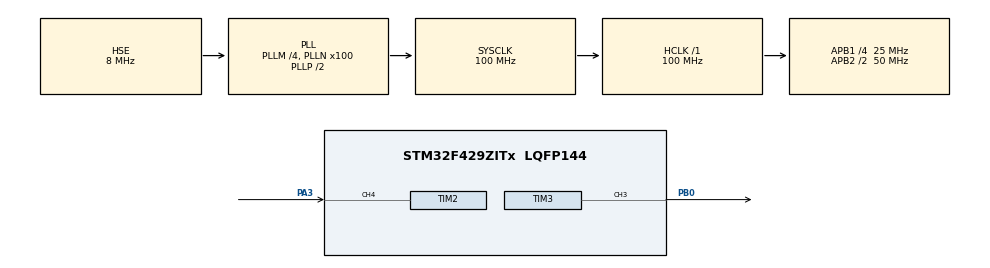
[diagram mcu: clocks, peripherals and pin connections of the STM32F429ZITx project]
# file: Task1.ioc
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Mcu.Family=STM32F4
Mcu.Name=STM32F429ZITx
Mcu.Package=LQFP144
NVIC.PriorityGroup=NVIC_PRIORITYGROUP_4
NVIC.TIM2_IRQn=true\:0\:0\:false\:false\:true\:true\:true
NVIC.TIM3_IRQn=true\:0\:0\:false\:false\:true\:true\:true
PA3.Signal=S_TIM2_CH4
PB0.Signal=S_TIM3_CH3
PH0/OSC_IN.Mode=HSE-External-Oscillator
PH0/OSC_IN.Signal=RCC_OSC_IN
PH1/OSC_OUT.Mode=HSE-External-Oscillator
PH1/OSC_OUT.Signal=RCC_OSC_OUT
ProjectManager.HeapSize=0x200
ProjectManager.StackSize=0x400
ProjectManager.TargetToolchain=EWARM V8.32
RCC.48MHZClocksFreq_Value=50000000
RCC.AHBFreq_Value=100000000
RCC.APB1CLKDivider=RCC_HCLK_DIV4
RCC.APB1Freq_Value=25000000
RCC.APB1TimFreq_Value=50000000
RCC.APB2CLKDivider=RCC_HCLK_DIV2
RCC.APB2Freq_Value=50000000
RCC.APB2TimFreq_Value=100000000
RCC.CortexFreq_Value=100000000
RCC.HCLKFreq_Value=100000000
RCC.HSE_VALUE=8000000
RCC.HSI_VALUE=16000000
RCC.LSE_VALUE=32768
RCC.PLLM=4
RCC.PLLN=100
RCC.PLLSourceVirtual=RCC_PLLSOURCE_HSE
RCC.SYSCLKFreq_VALUE=100000000
RCC.SYSCLKSource=RCC_SYSCLKSOURCE_PLLCLK
RCC.VCOOutputFreq_Value=200000000
SH.S_TIM2_CH4.0=TIM2_CH4,Input_Capture4_from_TI4
SH.S_TIM3_CH3.0=TIM3_CH3,Output Compare3 CH3
TIM2.Channel-Input_Capture4_from_TI4=TIM_CHANNEL_4
TIM2.ICPolarity_CH4=TIM_INPUTCHANNELPOLARITY_RISING
TIM2.Period=0xfffff-1
TIM2.Prescaler=99
TIM3.Channel-Output\ Compare3\ CH3=TIM_CHANNEL_3
TIM3.Period=0xffff-1
TIM3.Prescaler=99
VP_TIM2_VS_ClockSourceINT.Mode=Internal
VP_TIM3_VS_ClockSourceINT.Mode=Internal
VP_TIM4_VS_ClockSourceINT.Mode=Internal
board=custom

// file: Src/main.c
/* USER CODE BEGIN Header */
/**
  ******************************************************************************
  * @file           : main.c
  * @brief          : Main program body
  ******************************************************************************
  * @attention
  *
  * <h2><center>&copy; Copyright (c) 2020 STMicroelectronics.
  * All rights reserved.</center></h2>
  *
  * This software component is licensed by ST under BSD 3-Clause license,
  * the "License"; You may not use this file except in compliance with the
  * License. You may obtain a copy of the License at:
  *                        opensource.org/licenses/BSD-3-Clause
  *
  ******************************************************************************
  */
/* USER CODE END Header */

#include "main.h"

/* USER CODE BEGIN Includes */
#include "stdio.h"
/* USER CODE END Includes */

TIM_HandleTypeDef htim2;
TIM_HandleTypeDef htim3;
TIM_HandleTypeDef htim4;

void SystemClock_Config(void);
static void MX_GPIO_Init(void);
static void MX_TIM2_Init(void);
static void MX_TIM4_Init(void);
static void MX_TIM3_Init(void);

/* USER CODE BEGIN 0 */

uint16_t IC_Val1 = 0;
uint16_t IC_Val2 = 0;
uint16_t Difference = 0;
uint16_t Difference1 = 0;

uint8_t Is_First_Captured = 0;  // is the first value captured ?

// Let's write the callbacl function now

void HAL_TIM_IC_CaptureCallback(TIM_HandleTypeDef *htim)
{
	if (htim->Channel == HAL_TIM_ACTIVE_CHANNEL_4)  // if the interrupt source is channel4
	{
		if (Is_First_Captured==0) // if the first value is not captured
		{
			IC_Val1 = HAL_TIM_ReadCapturedValue(htim, TIM_CHANNEL_4); // read the first value

                        if (IC_Val1 > IC_Val2)
			{
				Difference1 = IC_Val1-IC_Val2;
                                printf("lower pw = %d" , Difference1);
			}

			Is_First_Captured = 1;  // set the first captured as true
			// Now change the polarity to falling edge
			__HAL_TIM_SET_CAPTUREPOLARITY(htim, TIM_CHANNEL_4, TIM_INPUTCHANNELPOLARITY_FALLING);
		}

		else if (Is_First_Captured==1)   // if the first is already captured
		{
			IC_Val2 = HAL_TIM_ReadCapturedValue(htim, TIM_CHANNEL_4);  // read second value
			__HAL_TIM_SET_COUNTER(htim, 0);  // reset the counter

			if (IC_Val2 > IC_Val1)
			{
				Difference = IC_Val2-IC_Val1;
                                printf("upper pw = %d" , Difference);
			}

			Is_First_Captured = 0; // set it back to false

			// set polarity to rising edge
			__HAL_TIM_SET_CAPTUREPOLARITY(htim, TIM_CHANNEL_4, TIM_INPUTCHANNELPOLARITY_RISING);

		}
	}
}

/* USER CODE END 0 */

int main(void)
{

  /* MCU Configuration--------------------------------------------------------*/

  /* Reset of all peripherals, Initializes the Flash interface and the Systick. */
  HAL_Init();

  /* Configure the system clock */
  SystemClock_Config();

  /* Initialize all configured peripherals */
  MX_GPIO_Init();
  MX_TIM2_Init();
  MX_TIM4_Init();
  MX_TIM3_Init();

  /* Infinite loop */
  while (1)
  {

  }
}

void SystemClock_Config(void)
{
  RCC_OscInitTypeDef RCC_OscInitStruct = {0};
  RCC_ClkInitTypeDef RCC_ClkInitStruct = {0};

  /** Configure the main internal regulator output voltage
  */
  __HAL_RCC_PWR_CLK_ENABLE();
  __HAL_PWR_VOLTAGESCALING_CONFIG(PWR_REGULATOR_VOLTAGE_SCALE3);
  /** Initializes the CPU, AHB and APB busses clocks
  */
  RCC_OscInitStruct.OscillatorType = RCC_OSCILLATORTYPE_HSE;
  RCC_OscInitStruct.HSEState = RCC_HSE_ON;
  RCC_OscInitStruct.PLL.PLLState = RCC_PLL_ON;
  RCC_OscInitStruct.PLL.PLLSource = RCC_PLLSOURCE_HSE;
  RCC_OscInitStruct.PLL.PLLM = 4;
  RCC_OscInitStruct.PLL.PLLN = 100;
  RCC_OscInitStruct.PLL.PLLP = RCC_PLLP_DIV2;
  RCC_OscInitStruct.PLL.PLLQ = 4;
  if (HAL_RCC_OscConfig(&RCC_OscInitStruct) != HAL_OK)
  {
    Error_Handler();
  }
  /** Initializes the CPU, AHB and APB busses clocks
  */
  RCC_ClkInitStruct.ClockType = RCC_CLOCKTYPE_HCLK|RCC_CLOCKTYPE_SYSCLK
                              |RCC_CLOCKTYPE_PCLK1|RCC_CLOCKTYPE_PCLK2;
  RCC_ClkInitStruct.SYSCLKSource = RCC_SYSCLKSOURCE_PLLCLK;
  RCC_ClkInitStruct.AHBCLKDivider = RCC_SYSCLK_DIV1;
  RCC_ClkInitStruct.APB1CLKDivider = RCC_HCLK_DIV4;
  RCC_ClkInitStruct.APB2CLKDivider = RCC_HCLK_DIV2;

  if (HAL_RCC_ClockConfig(&RCC_ClkInitStruct, FLASH_LATENCY_3) != HAL_OK)
  {
    Error_Handler();
  }
}

static void MX_TIM2_Init(void)
{

  TIM_ClockConfigTypeDef sClockSourceConfig = {0};
  TIM_MasterConfigTypeDef sMasterConfig = {0};
  TIM_IC_InitTypeDef sConfigIC = {0};

  htim2.Instance = TIM2;
  htim2.Init.Prescaler = 99;
  htim2.Init.CounterMode = TIM_COUNTERMODE_UP;
  htim2.Init.Period = 0xfffff-1;
  htim2.Init.ClockDivision = TIM_CLOCKDIVISION_DIV1;
  htim2.Init.AutoReloadPreload = TIM_AUTORELOAD_PRELOAD_DISABLE;
  if (HAL_TIM_Base_Init(&htim2) != HAL_OK)
  {
    Error_Handler();
  }
  sClockSourceConfig.ClockSource = TIM_CLOCKSOURCE_INTERNAL;
  if (HAL_TIM_ConfigClockSource(&htim2, &sClockSourceConfig) != HAL_OK)
  {
    Error_Handler();
  }
  if (HAL_TIM_IC_Init(&htim2) != HAL_OK)
  {
    Error_Handler();
  }
  sMasterConfig.MasterOutputTrigger = TIM_TRGO_RESET;
  sMasterConfig.MasterSlaveMode = TIM_MASTERSLAVEMODE_DISABLE;
  if (HAL_TIMEx_MasterConfigSynchronization(&htim2, &sMasterConfig) != HAL_OK)
  {
    Error_Handler();
  }
  sConfigIC.ICPolarity = TIM_INPUTCHANNELPOLARITY_RISING;
  sConfigIC.ICSelection = TIM_ICSELECTION_DIRECTTI;
  sConfigIC.ICPrescaler = TIM_ICPSC_DIV1;
  sConfigIC.ICFilter = 0;
  if (HAL_TIM_IC_ConfigChannel(&htim2, &sConfigIC, TIM_CHANNEL_4) != HAL_OK)
  {
    Error_Handler();
  }

}

static void MX_TIM3_Init(void)
{

  TIM_ClockConfigTypeDef sClockSourceConfig = {0};
  TIM_MasterConfigTypeDef sMasterConfig = {0};
  TIM_OC_InitTypeDef sConfigOC = {0};

  htim3.Instance = TIM3;
  htim3.Init.Prescaler = 99;
  htim3.Init.CounterMode = TIM_COUNTERMODE_UP;
  htim3.Init.Period = 0xffff-1;
  htim3.Init.ClockDivision = TIM_CLOCKDIVISION_DIV1;
  htim3.Init.AutoReloadPreload = TIM_AUTORELOAD_PRELOAD_DISABLE;
  if (HAL_TIM_Base_Init(&htim3) != HAL_OK)
  {
    Error_Handler();
  }
  sClockSourceConfig.ClockSource = TIM_CLOCKSOURCE_INTERNAL;
  if (HAL_TIM_ConfigClockSource(&htim3, &sClockSourceConfig) != HAL_OK)
  {
    Error_Handler();
  }
  if (HAL_TIM_OC_Init(&htim3) != HAL_OK)
  {
    Error_Handler();
  }
  sMasterConfig.MasterOutputTrigger = TIM_TRGO_RESET;
  sMasterConfig.MasterSlaveMode = TIM_MASTERSLAVEMODE_DISABLE;
  if (HAL_TIMEx_MasterConfigSynchronization(&htim3, &sMasterConfig) != HAL_OK)
  {
    Error_Handler();
  }
  sConfigOC.OCMode = TIM_OCMODE_TIMING;
  sConfigOC.Pulse = 0;
  sConfigOC.OCPolarity = TIM_OCPOLARITY_HIGH;
  sConfigOC.OCFastMode = TIM_OCFAST_DISABLE;
  if (HAL_TIM_OC_ConfigChannel(&htim3, &sConfigOC, TIM_CHANNEL_3) != HAL_OK)
  {
    Error_Handler();
  }
  HAL_TIM_MspPostInit(&htim3);

}

static void MX_TIM4_Init(void)
{

  TIM_ClockConfigTypeDef sClockSourceConfig = {0};
  TIM_MasterConfigTypeDef sMasterConfig = {0};

  htim4.Instance = TIM4;
  htim4.Init.Prescaler = 0;
  htim4.Init.CounterMode = TIM_COUNTERMODE_UP;
  htim4.Init.Period = 0;
  htim4.Init.ClockDivision = TIM_CLOCKDIVISION_DIV1;
  htim4.Init.AutoReloadPreload = TIM_AUTORELOAD_PRELOAD_DISABLE;
  if (HAL_TIM_Base_Init(&htim4) != HAL_OK)
  {
    Error_Handler();
  }
  sClockSourceConfig.ClockSource = TIM_CLOCKSOURCE_INTERNAL;
  if (HAL_TIM_ConfigClockSource(&htim4, &sClockSourceConfig) != HAL_OK)
  {
    Error_Handler();
  }
  sMasterConfig.MasterOutputTrigger = TIM_TRGO_RESET;
  sMasterConfig.MasterSlaveMode = TIM_MASTERSLAVEMODE_DISABLE;
  if (HAL_TIMEx_MasterConfigSynchronization(&htim4, &sMasterConfig) != HAL_OK)
  {
    Error_Handler();
  }

}

static void MX_GPIO_Init(void)
{

  /* GPIO Ports Clock Enable */
  __HAL_RCC_GPIOH_CLK_ENABLE();
  __HAL_RCC_GPIOA_CLK_ENABLE();
  __HAL_RCC_GPIOB_CLK_ENABLE();

}

void Error_Handler(void)
{
}

/************************ (C) COPYRIGHT STMicroelectronics *****END OF FILE****/
